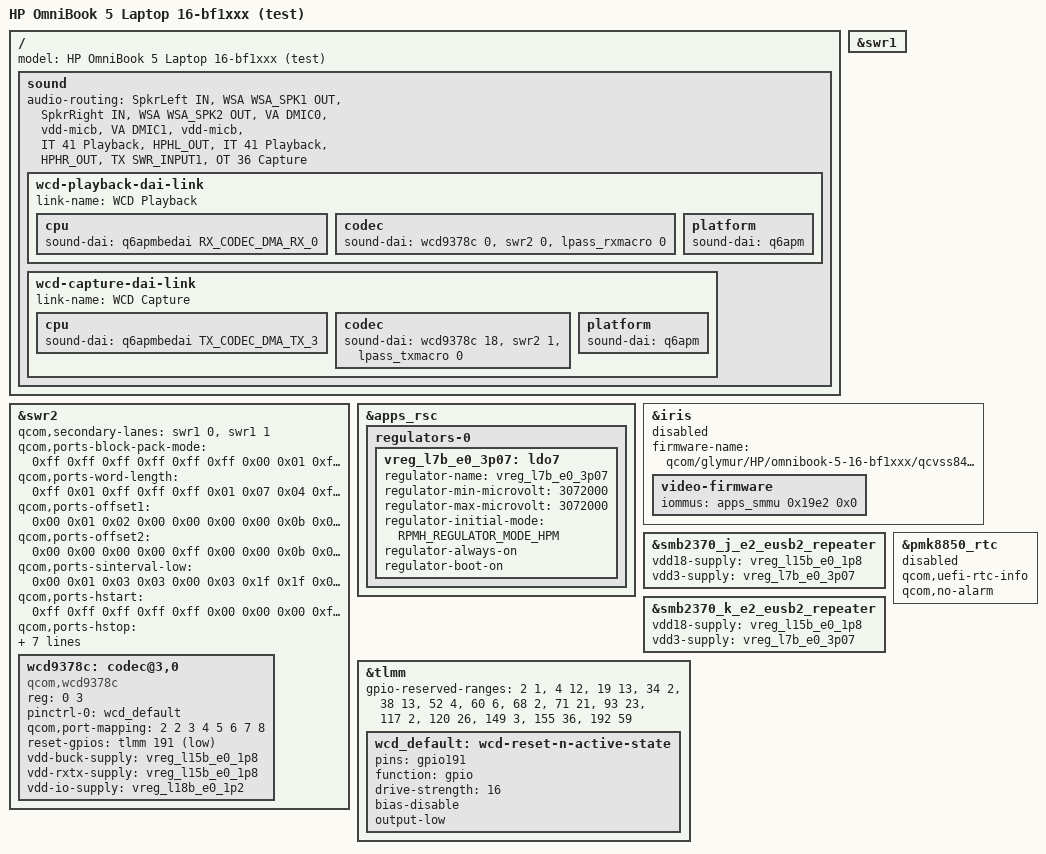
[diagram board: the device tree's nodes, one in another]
// SPDX-License-Identifier: BSD-3-Clause
/*
 * HP OmniBook 5 16-bf1xxx, test device tree: the daily device tree plus
 * what is being tested. Booted by the GRUB entry "Ubuntu on SSD: test
 * device tree". Once an item here is proven, it moves into the daily
 * device tree.
 *
 * In test from kernel -11:
 * - the SMB2370 eUSB2 repeaters of the USB-C ports (from kernel -8, for
 *   full and low speed);
 * - the EC's event line, with the pull-up HP's ACPI sets on it.
 *
 * In test from kernel -13 (test DTB only):
 * - the speakers and the two microphones (second version: both amplifiers
 *   on swr0; from kernel -14 reset through LPASS TLMM GPIO 12).
 *
 * In test from kernel -15:
 * - the Iris video decoder and encoder, as on the Glymur CRD (which the
 *   Mahua CRD includes), with HP's signed video firmware;
 * - DisplayPort over both USB-C ports (DP alt mode);
 * - HP's skin-temperature limits on the EC thermistors.
 *
 * Changed for kernel -16 (docs/kernel-16-plan-2026-10-21.md):
 * - the EC thermal zones are named ec-therm1..4-thermal (the kernel limits
 *   zone names to 19 characters; the -15 names made the EC probe fail);
 * - the speaker amplifiers get their two supplies, L15B and L18B, which
 *   are held on at HP's voltages;
 * - Iris uses the one-core Mahua variant (qcom,mahua-iris);
 * - DisplayPort is off again: plugging a monitor crashed -15.
 *
 * Changed after kernel -16 (docs/audit-2026-10-22.md):
 * - Iris is off again: HP's video firmware refused the driver's
 *   configuration with one core as with two, and the one-core patch is
 *   dropped.
 *
 * Changed for kernel -17 (docs/video-iris-fuse-2026-10-23.md):
 * - Iris is on again, as on -15, for one logged experiment with the
 *   default-off diagnostics of glymur-bringup/0003 (qcom_iris.diag_cores,
 *   diag_pipes, diag_core_id). Without them the second core fails to power
 *   on and every open fails, as on -15; nothing else depends on Iris.
 * - the PMK8850 PMIC (power key, PMIC GPIOs, ADC, RTC), as every Glymur
 *   and Mahua laptop upstream includes it, with the RTC taking its offset
 *   from UEFI read-only (docs/uefi-variables-2026-10-23.md).
 *
 * Changed for kernel -18 (docs/kernel-18-plan-2026-10-23.md):
 * - Iris is off again: on -17 every open failed to power the second core,
 *   and WirePlumber's v4l2 monitor stalled on it. The firmware accepted
 *   core ID 2 (docs/runbook-results-17-2026-10-23.md).
 * - the PMK8850 RTC is off: HP's firmware has no RTCInfo variable, so the
 *   driver failed with -ENOENT. Windows reads the time through the ADSP's
 *   PMIC GLink service (\_SB.PRTC._GRT), which Linux does not have.
 *
 * In test from kernel -19 (docs/kernel-19-plan-2026-11-05.md):
 * - the headset jack: the WCD9378 (Tambora) codec on swr2, with swr1 as its
 *   second pair of data lanes, wired as Qualcomm's Glymur CRD wires it
 *   (glymur-crd.dtsi in qcom-next), with HP's values where they differ.
 * - USB full and low speed: LDO7_B (3.072 V, HP's USB vote) always on, and
 *   the USB-C repeaters' vdd18/vdd3 supplies.
 *
 * Kernel -20 (docs/kernel-20-plan-2026-11-09.md): the EC event line, the
 * skin-temperature zones, the speakers and microphones and the USB-C
 * repeaters moved to the daily device tree. What stays here: the PMK8850,
 * the headset, LDO7_B and the repeaters' supplies. The
 * RTC comes from the ADSP's PMIC GLink service (rtc-qcom-glink, no node of
 * its own); suspend, the M31 PHY's SE0 timeout and the xHCI reset on resume
 * are kernel changes. Iris and DisplayPort are in the -test-av device tree.
 */
/dts-v1/;

#include <dt-bindings/regulator/qcom,rpmh-regulator.h>
#include <dt-bindings/sound/qcom,q6dsp-lpass-ports.h>
#include "mahua-hp-omnibook-5-bf1xxx.dts"
#include "pmk8850.dtsi"

/ {
	model = "HP OmniBook 5 Laptop 16-bf1xxx (test)";

	/*
	 * Headset additions to the daily device tree's sound card (from -19):
	 * the WCD9378's playback and capture links and their routes.
	 */
	sound {
		audio-routing = "SpkrLeft IN", "WSA WSA_SPK1 OUT",
				"SpkrRight IN", "WSA WSA_SPK2 OUT",
				"VA DMIC0", "vdd-micb",
				"VA DMIC1", "vdd-micb",
				"IT 41 Playback", "HPHL_OUT",
				"IT 41 Playback", "HPHR_OUT",
				/* headset mic: WCD9378 OT 36 (DP2) into the TX macro */
				"TX SWR_INPUT1", "OT 36 Capture";

		/* headset: swr2 cell 0 is its playback port, cell 1 capture */
		wcd-playback-dai-link {
			link-name = "WCD Playback";

			cpu {
				sound-dai = <&q6apmbedai RX_CODEC_DMA_RX_0>;
			};

			codec {
				sound-dai = <&wcd9378c 0>, <&swr2 0>, <&lpass_rxmacro 0>;
			};

			platform {
				sound-dai = <&q6apm>;
			};
		};

		wcd-capture-dai-link {
			link-name = "WCD Capture";

			cpu {
				sound-dai = <&q6apmbedai TX_CODEC_DMA_TX_3>;
			};

			codec {
				sound-dai = <&wcd9378c 18>, <&swr2 1>, <&lpass_txmacro 0>;
			};

			platform {
				sound-dai = <&q6apm>;
			};
		};
	};
};

/*
 * Headset jack (docs/audio-headset-path-2026-10-17.md,
 * docs/kernel-19-plan-2026-11-05.md). The only SoundWire peripheral HP's
 * ACPI lists besides the amplifiers is MAN_0217 PART_0110, the WCD9378. As
 * on the Glymur CRD (whose audio configuration HP's Windows drivers run),
 * swr2 is the bus master and swr1 adds data lanes 2 and 3; HP's QSJ0 maps
 * lanes 1-4 to the manager's lanes 1-4, its data ports are 2 (capture) and
 * 6, 7, 8 (playback), as below. The per-port values are the CRD's.
 * From HP's evidence: reset on GPIO 191 (DSDT ASCD GpioIo), vdd-buck and
 * vdd-rxtx on L15B 1.8 V (ACDResources.bin, ASCDResources.bin). vdd-io is
 * L18B 1.2 V as on the CRD; no audio device votes it, but it is held on
 * for the amplifiers anyway. Not described, because nothing here evidences
 * them: the mic-bias supply (the CRD's BOB1; left as a dummy regulator,
 * BOB stays on as the parent of the LDOs), HP's GpioInt on GPIO 193 (the
 * codec signals jack events in band), and HP's GpioIo pin 2. The unique
 * ID 3 is the CRD's; HP's _ADR does not give it.
 */
&swr1 {
	/* data lanes only: no bus master and no peripherals of its own */
	#qcom,swrm-lane-cells = <1>;

	status = "okay";
};

&swr2 {
	qcom,secondary-lanes = <&swr1 0>, <&swr1 1>;

	qcom,ports-block-pack-mode =
		/bits/ 8 <0xff 0xff 0xff 0xff 0xff 0xff 0x00
			  0x01 0xff 0xff 0xff 0xff 0xff 0xff>;
	qcom,ports-word-length =
		/bits/ 8 <0xff 0x01 0xff 0xff 0xff 0x01 0x07
			  0x04 0xff 0xff 0xff 0xff 0xff 0xff>;
	qcom,ports-offset1 =
		/bits/ 8 <0x00 0x01 0x02 0x00 0x00 0x00 0x00
			  0x0b 0x00 0x00 0x00 0x00 0x00 0x00>;
	qcom,ports-offset2 =
		/bits/ 8 <0x00 0x00 0x00 0x00 0xff 0x00 0x00
			  0x0b 0x00 0x00 0x00 0x00 0x00 0x00>;
	qcom,ports-sinterval-low =
		/bits/ 8 <0x00 0x01 0x03 0x03 0x00 0x03 0x1f
			  0x1f 0x00 0x00 0x00 0x00 0x00 0x00>;
	qcom,ports-hstart =
		/bits/ 8 <0xff 0xff 0xff 0xff 0xff 0x00 0x00
			  0x00 0xff 0xff 0xff 0xff 0xff 0xff>;
	qcom,ports-hstop =
		/bits/ 8 <0xff 0x0f 0xff 0xff 0xff 0x0f 0x0f
			  0x0f 0xff 0xff 0xff 0xff 0xff 0xff>;
	qcom,ports-lane-control =
		/bits/ 8 <0xff 0x01 0x00 0x01 0xff 0x03 0x02
			  0x02 0xff 0xff 0xff 0xff 0xff 0xff>;
	qcom,ports-ch-mask =
		/bits/ 8 <0xff 0x01 0xff 0xff 0xff 0x03 0x01
			  0x03 0xff 0xff 0xff 0xff 0xff 0xff>;
	qcom,ports-block-group-count =
		/bits/ 8 <0xff 0xff 0xff 0xff 0xff 0xff 0xff
			  0xff 0xff 0xff 0xff 0xff 0xff 0xff>;

	status = "okay";

	wcd9378c: codec@3,0 {
		compatible = "qcom,wcd9378c", "sdw20217011000";
		reg = <0 3>;

		pinctrl-0 = <&wcd_default>;
		pinctrl-names = "default";

		qcom,port-mapping = <2 2 3 4 5 6 7 8>;

		reset-gpios = <&tlmm 191 GPIO_ACTIVE_LOW>;

		vdd-buck-supply = <&vreg_l15b_e0_1p8>;
		vdd-rxtx-supply = <&vreg_l15b_e0_1p8>;
		vdd-io-supply = <&vreg_l18b_e0_1p2>;

		#sound-dai-cells = <1>;
	};
};

/*
 * LDO7_B for the eUSB2 repeaters' 3 V side (from -19), added to the daily
 * device tree's PMH0101 regulators.
 */
&apps_rsc {
	regulators-0 {
		/*
		 * From kernel -19, for USB full and low speed: LDO7_B at
		 * 3.072 V, which HP's PEP tables vote for every USB port and
		 * nothing else (\_SB.URS0.USB0, URS1.USB1, URS2.USB2 and their
		 * device-mode functions; off only in D3). It is the 3 V side of
		 * an eUSB2 repeater (the CRD's vdd3, there at 2.79 V), which
		 * full- and low-speed signalling needs. Shared by all ports, so
		 * always on.
		 */
		vreg_l7b_e0_3p07: ldo7 {
			regulator-name = "vreg_l7b_e0_3p07";
			regulator-min-microvolt = <3072000>;
			regulator-max-microvolt = <3072000>;
			regulator-initial-mode = <RPMH_REGULATOR_MODE_HPM>;
			regulator-always-on;
			regulator-boot-on;
		};
	};
};

/*
 * DisplayPort over USB-C (docs/external-display-2026-10-20.md) is off again
 * after kernel -15: with &mdss_dp0 and &mdss_dp1 enabled, plugging a monitor
 * made the EDID read fail, then the display controller timed out until the
 * machine reset (docs/runbook-results-2026-10-21.md). The two nodes, the
 * USB-C PHY links and the pmic_glink altmode ports stay as glymur.dtsi has
 * them. To test again, enable &mdss_dp0 and &mdss_dp1 with
 * link-frequencies = /bits/ 64 <1620000000 2700000000 5400000000
 * 8100000000> on their out endpoints, and read
 * docs/kernel-16-plan-2026-10-21.md first.
 */

/*
 * Iris video codec (docs/video-iris-2026-10-20.md), with HP's signed video
 * firmware. With Glymur's data the second core's GDSC never came on (-15),
 * and with one core the firmware refused Glymur's core and pipe settings
 * against its fuse word (-16). On -17 this is a test of the alternatives
 * through the diagnostics' module parameters
 * (docs/video-iris-fuse-2026-10-23.md), not a working configuration.
 */
&iris {
	firmware-name = "qcom/glymur/HP/omnibook-5-16-bf1xxx/qcvss8480.mbn";

	/* off until the second core powers on (-18 plan) */
	status = "disabled";

	video-firmware {
		iommus = <&apps_smmu 0x19e2 0x0>;
	};
};

/*
 * The USB-C repeaters are in the daily device tree from -20. From -19 they
 * get HP's USB rails here: L15B 1.8 V and L7B 3.072 V (vdd18, vdd3).
 */
&smb2370_j_e2_eusb2_repeater {
	vdd18-supply = <&vreg_l15b_e0_1p8>;
	vdd3-supply = <&vreg_l7b_e0_3p07>;
};

&smb2370_k_e2_eusb2_repeater {
	vdd18-supply = <&vreg_l15b_e0_1p8>;
	vdd3-supply = <&vreg_l7b_e0_3p07>;
};

&tlmm {
	/*
	 * The daily allow-list plus the headset codec's reset (GPIO 191)
	 */
	gpio-reserved-ranges = <2 1>, <4 12>, <19 13>, <34 2>, <38 13>,
			       <52 4>, <60 6>, <68 2>, <71 21>, <93 23>,
			       <117 2>, <120 26>, <149 3>, <155 36>,
			       <192 59>;

	/* the CRD's state for the WCD9378 reset line */
	wcd_default: wcd-reset-n-active-state {
		pins = "gpio191";
		function = "gpio";
		drive-strength = <16>;
		bias-disable;
		output-low;
	};
};

/*
 * PMK8850 RTC (PMIC "A", whose clocks HP's PEP tables vote): the counter
 * runs from the PMIC, the offset to wall time is the UEFI variable Windows
 * keeps (qcom,uefi-rtc-info), as on the ASUS Zenbook A16 and the Glymur
 * QCB. Without allow-set-time Linux only reads the variable. No alarm, as
 * on the Glymur CRD, the QCB and the Zenbook A16.
 */
&pmk8850_rtc {
	qcom,uefi-rtc-info;
	qcom,no-alarm;

	/*
	 * No RTCInfo on this firmware: off. From -19 the RTC is the ADSP's
	 * PMIC GLink RTC service, which Windows uses (\_SB.PRTC).
	 */
	status = "disabled";
};
